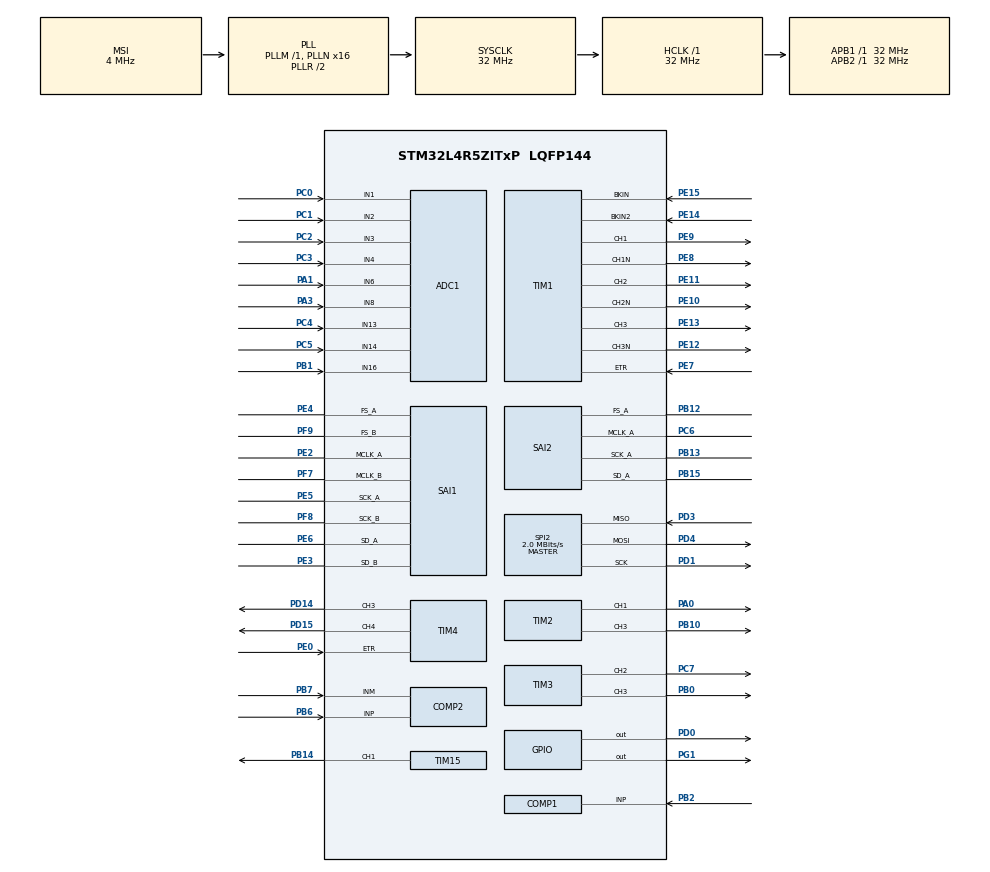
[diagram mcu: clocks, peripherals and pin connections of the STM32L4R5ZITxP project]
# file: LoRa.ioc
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ADC1.Channel-0\#ChannelRegularConversion=ADC_CHANNEL_1
ADC1.NbrOfConversionFlag=1
ADC1.OffsetNumber-0\#ChannelRegularConversion=ADC_OFFSET_NONE
ADC1.Rank-0\#ChannelRegularConversion=1
ADC1.SamplingTime-0\#ChannelRegularConversion=ADC_SAMPLETIME_2CYCLES_5
ADC1.master=1
Mcu.Family=STM32L4
Mcu.Name=STM32L4R5ZITxP
Mcu.Package=LQFP144
NVIC.PriorityGroup=NVIC_PRIORITYGROUP_4
PA0.Signal=S_TIM2_CH1
PA1.Signal=ADCx_IN6
PA10.Signal=USB_OTG_FS_ID
PA13\ (JTMS/SWDIO).Mode=Serial_Wire
PA13\ (JTMS/SWDIO).Signal=SYS_JTMS-SWDIO
PA14\ (JTCK/SWCLK).Mode=Serial_Wire
PA14\ (JTCK/SWCLK).Signal=SYS_JTCK-SWCLK
PA3.Signal=ADCx_IN8
PA4.Signal=SPI1_NSS
PA5.Signal=SPI1_SCK
PA6.Signal=SPI1_MISO
PA7.Signal=SPI1_MOSI
PA8.Signal=USB_OTG_FS_SOF
PA9.Signal=USB_OTG_FS_VBUS
PB0.Signal=S_TIM3_CH3
PB1.Signal=ADCx_IN16
PB10.Signal=S_TIM2_CH3
PB12.Mode=SAI_A_MasterWithClock
PB12.Signal=SAI2_FS_A
PB13.Mode=SAI_A_MasterWithClock
PB13.Signal=SAI2_SCK_A
PB14.Signal=S_TIM15_CH1
PB15.Mode=SAI_A_MasterWithClock
PB15.Signal=SAI2_SD_A
PB2.Mode=INP
PB2.Signal=COMP1_INP
PB3\ (JTDO/TRACESWO).Signal=SPI3_SCK
PB4\ (NJTRST).Signal=SPI3_MISO
PB5.Signal=SPI3_MOSI
PB6.Mode=INP
PB6.Signal=COMP2_INP
PB7.Mode=INM
PB7.Signal=COMP2_INM
PB8.GPIO_Pu=GPIO_PULLUP
PB8.Signal=I2C1_SCL
PB9.GPIO_Pu=GPIO_PULLUP
PB9.Signal=I2C1_SDA
PC0.Signal=ADCx_IN1
PC1.Signal=ADCx_IN2
PC10.Signal=SDMMC1_D2
PC11.Signal=SDMMC1_D3
PC12.Signal=SDMMC1_CK
PC13.Mode=SYS_WakeUp1
PC13.Signal=SYS_WKUP2
PC14-OSC32_IN\ (PC14).Mode=LSE-External-Oscillator
PC14-OSC32_IN\ (PC14).Signal=RCC_OSC32_IN
PC15-OSC32_OUT\ (PC15).Mode=LSE-External-Oscillator
PC15-OSC32_OUT\ (PC15).Signal=RCC_OSC32_OUT
PC2.Signal=ADCx_IN3
PC3.Signal=ADCx_IN4
PC4.Signal=ADCx_IN13
PC5.Signal=ADCx_IN14
PC6.Mode=SAI_A_MasterWithClock
PC6.Signal=SAI2_MCLK_A
PC7.Signal=S_TIM3_CH2
PC8.Signal=SDMMC1_D0
PC9.Signal=SDMMC1_D1
PD0.PinState=GPIO_PIN_SET
PD0.Signal=GPIO_Output
PD1.Mode=Full_Duplex_Master
PD1.Signal=SPI2_SCK
PD14.Signal=S_TIM4_CH3
PD15.Signal=S_TIM4_CH4
PD2.Signal=SDMMC1_CMD
PD3.Mode=Full_Duplex_Master
PD3.Signal=SPI2_MISO
PD4.Mode=Full_Duplex_Master
PD4.Signal=SPI2_MOSI
PD5.Signal=USART2_TX
PD6.Signal=USART2_RX
PD8.Signal=USART3_TX
PD9.Signal=USART3_RX
PE0.Signal=S_TIM4_ETR
PE10.Mode=PWM Generation2 CH2 CH2N
PE10.Signal=TIM1_CH2N
PE11.Signal=S_TIM1_CH2
PE12.Mode=PWM Generation3 CH3 CH3N
PE12.Signal=TIM1_CH3N
PE13.Signal=S_TIM1_CH3
PE14.Mode=Activate-Break-Input-2
PE14.Signal=TIM1_BKIN2
PE15.Mode=Activate-Break-Input
PE15.Signal=TIM1_BKIN
PE2.Mode=SAI_A_MasterWithClock
PE2.Signal=SAI1_MCLK_A
PE3.Mode=SAI_B_MasterWithClock
PE3.Signal=SAI1_SD_B
PE4.Mode=SAI_A_MasterWithClock
PE4.Signal=SAI1_FS_A
PE5.Mode=SAI_A_MasterWithClock
PE5.Signal=SAI1_SCK_A
PE6.Mode=SAI_A_MasterWithClock
PE6.Signal=SAI1_SD_A
PE7.Signal=S_TIM1_ETR
PE8.Mode=PWM Generation1 CH1 CH1N
PE8.Signal=TIM1_CH1N
PE9.Signal=S_TIM1_CH1
PF0.GPIO_Pu=GPIO_PULLUP
PF0.Signal=I2C2_SDA
PF1.GPIO_Pu=GPIO_PULLUP
PF1.Signal=I2C2_SCL
PF2.GPIO_Pu=GPIO_PULLUP
PF2.Signal=I2C2_SMBA
PF7.Mode=SAI_B_MasterWithClock
PF7.Signal=SAI1_MCLK_B
PF8.Mode=SAI_B_MasterWithClock
PF8.Signal=SAI1_SCK_B
PF9.Mode=SAI_B_MasterWithClock
PF9.Signal=SAI1_FS_B
PG1.Signal=GPIO_Output
PG7.Signal=LPUART1_TX
PG8.Signal=LPUART1_RX
PH0-OSC_IN\ (PH0).Mode=HSE-External-Oscillator
PH0-OSC_IN\ (PH0).Signal=RCC_OSC_IN
PH1-OSC_OUT\ (PH1).Mode=HSE-External-Oscillator
PH1-OSC_OUT\ (PH1).Signal=RCC_OSC_OUT
ProjectManager.HeapSize=0x200
ProjectManager.StackSize=0x400
ProjectManager.TargetToolchain=STM32CubeIDE
RCC.ADCFreq_Value=48000000
RCC.AHBFreq_Value=32000000
RCC.APB1Freq_Value=32000000
RCC.APB1TimFreq_Value=32000000
RCC.APB2Freq_Value=32000000
RCC.APB2TimFreq_Value=32000000
RCC.CortexFreq_Value=32000000
RCC.HCLKFreq_Value=32000000
RCC.HSE_VALUE=8000000
RCC.HSI48_VALUE=48000000
RCC.HSI_VALUE=16000000
RCC.MSI_VALUE=4000000
RCC.PLLN=16
RCC.PLLSAI1N=24
RCC.SYSCLKFreq_VALUE=32000000
RCC.SYSCLKSource=RCC_SYSCLKSOURCE_PLLCLK
RCC.USBFreq_Value=48000000
RCC.VCOOutputFreq_Value=64000000
SAI1.InitProtocol-SAI_A_MasterWithClock=Enable
SAI1.Instance-SAI_A_MasterWithClock=SAI$Index_Block_A
SAI1.Instance-SAI_B_MasterWithClock=SAI$Index_Block_B
SAI1.MClockEnable-SAI_A_MasterWithClock=SAI_MASTERCLOCK_ENABLE
SAI1.MClockEnable-SAI_B_MasterWithClock=SAI_MASTERCLOCK_ENABLE
SAI1.Synchro-SAI_A_MasterWithClock=SAI_ASYNCHRONOUS
SAI1.Synchro-SAI_B_MasterWithClock=SAI_ASYNCHRONOUS
SAI1.VirtualMode-SAI_A_MasterWithClock=VM_MASTER
SAI1.VirtualMode-SAI_B_MasterWithClock=VM_MASTER
SAI1.VirtualProtocol-SAI_A_BASIC=VM_BASIC_PROTOCOL
SAI2.Instance-SAI_A_MasterWithClock=SAI$Index_Block_A
SAI2.MClockEnable-SAI_A_MasterWithClock=SAI_MASTERCLOCK_ENABLE
SAI2.Synchro-SAI_A_MasterWithClock=SAI_ASYNCHRONOUS
SAI2.VirtualMode-SAI_A_MasterWithClock=VM_MASTER
SH.ADCx_IN1.0=ADC1_IN1,IN1-Single-Ended
SH.ADCx_IN13.0=ADC1_IN13,IN13-Single-Ended
SH.ADCx_IN14.0=ADC1_IN14,IN14-Single-Ended
SH.ADCx_IN16.0=ADC1_IN16,IN16-Single-Ended
SH.ADCx_IN2.0=ADC1_IN2,IN2-Single-Ended
SH.ADCx_IN3.0=ADC1_IN3,IN3-Single-Ended
SH.ADCx_IN4.0=ADC1_IN4,IN4-Single-Ended
SH.ADCx_IN6.0=ADC1_IN6,IN6-Single-Ended
SH.ADCx_IN8.0=ADC1_IN8,IN8-Single-Ended
SH.S_TIM15_CH1.0=TIM15_CH1,PWM Generation1 CH1
SH.S_TIM1_CH1.0=TIM1_CH1,PWM Generation1 CH1 CH1N
SH.S_TIM1_CH2.0=TIM1_CH2,PWM Generation2 CH2 CH2N
SH.S_TIM1_CH3.0=TIM1_CH3,PWM Generation3 CH3 CH3N
SH.S_TIM1_ETR.0=TIM1_ETR,ETR-as-clearing-source
SH.S_TIM2_CH1.0=TIM2_CH1,PWM Generation1 CH1
SH.S_TIM2_CH3.0=TIM2_CH3,PWM Generation3 CH3
SH.S_TIM3_CH2.0=TIM3_CH2,PWM Generation2 CH2
SH.S_TIM3_CH3.0=TIM3_CH3,PWM Generation3 CH3
SH.S_TIM4_CH3.0=TIM4_CH3,PWM Generation3 CH3
SH.S_TIM4_CH4.0=TIM4_CH4,PWM Generation4 CH4
SH.S_TIM4_ETR.0=TIM4_ETR,ETR-as-clearing-source
SPI2.BaudRatePrescaler=SPI_BAUDRATEPRESCALER_16
SPI2.CalculateBaudRate=2.0 MBits/s
SPI2.DataSize=SPI_DATASIZE_8BIT
SPI2.Direction=SPI_DIRECTION_2LINES
SPI2.Mode=SPI_MODE_MASTER
SPI2.VirtualType=VM_MASTER
TIM1.Channel-PWM\ Generation1\ CH1\ CH1N=TIM_CHANNEL_1
TIM1.Channel-PWM\ Generation2\ CH2\ CH2N=TIM_CHANNEL_2
TIM1.Channel-PWM\ Generation3\ CH3\ CH3N=TIM_CHANNEL_3
TIM15.Channel-PWM\ Generation1\ CH1=TIM_CHANNEL_1
TIM2.Channel-PWM\ Generation1\ CH1=TIM_CHANNEL_1
TIM2.Channel-PWM\ Generation3\ CH3=TIM_CHANNEL_3
TIM3.Channel-PWM\ Generation2\ CH2=TIM_CHANNEL_2
TIM3.Channel-PWM\ Generation3\ CH3=TIM_CHANNEL_3
TIM4.Channel-PWM\ Generation3\ CH3=TIM_CHANNEL_3
TIM4.Channel-PWM\ Generation4\ CH4=TIM_CHANNEL_4
VP_COMP1_VS_VREFINT.Mode=VREFINT
VP_SAI1_VP_$IpInstance_SAIA_SAI_BASIC.Mode=SAI_A_BASIC
board=NUCLEO-L4R5ZI-P

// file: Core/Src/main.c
/* USER CODE BEGIN Header */
/**
  ******************************************************************************
  * @file           : main.c
  * @brief          : Main program body
  ******************************************************************************
  * @attention
  *
  * Copyright (c) 2024 STMicroelectronics.
  * All rights reserved.
  *
  * This software is licensed under terms that can be found in the LICENSE file
  * in the root directory of this software component.
  * If no LICENSE file comes with this software, it is provided AS-IS.
  *
  ******************************************************************************
  */
/* USER CODE END Header */
#include "main.h"

/* USER CODE BEGIN Includes */
#include "lora_sx1276.h"
/* USER CODE END Includes */

/* USER CODE BEGIN PD */
//#define RADIO_INIT_REGISTERS_VALUE                \
//{                                                 \
//    { MODEM_FSK , REG_LNA                , 0x23 },\
//    { MODEM_FSK , REG_RXCONFIG           , 0x1E },\
//    { MODEM_FSK , REG_RSSICONFIG         , 0xD2 },\
//    { MODEM_FSK , REG_AFCFEI             , 0x01 },\
//    { MODEM_FSK , REG_PREAMBLEDETECT     , 0xAA },\
//    { MODEM_FSK , REG_OSC                , 0x07 },\
//    { MODEM_FSK , REG_SYNCCONFIG         , 0x12 },\
//    { MODEM_FSK , REG_SYNCVALUE1         , 0xC1 },\
//    { MODEM_FSK , REG_SYNCVALUE2         , 0x94 },\
//    { MODEM_FSK , REG_SYNCVALUE3         , 0xC1 },\
//    { MODEM_FSK , REG_PACKETCONFIG1      , 0xD8 },\
//    { MODEM_FSK , REG_FIFOTHRESH         , 0x8F },\
//    { MODEM_FSK , REG_IMAGECAL           , 0x02 },\
//    { MODEM_FSK , REG_DIOMAPPING1        , 0x00 },\
//    { MODEM_FSK , REG_DIOMAPPING2        , 0x30 },\
//    { MODEM_LORA, REG_LR_PAYLOADMAXLENGTH, 0x40 },\
//}
/* USER CODE END PD */

ADC_HandleTypeDef hadc1;

COMP_HandleTypeDef hcomp1;
COMP_HandleTypeDef hcomp2;

SAI_HandleTypeDef hsai_BlockB1;
SAI_HandleTypeDef hsai_BlockA1;
SAI_HandleTypeDef hsai_BlockA2;

SPI_HandleTypeDef hspi2;

TIM_HandleTypeDef htim1;
TIM_HandleTypeDef htim2;
TIM_HandleTypeDef htim3;
TIM_HandleTypeDef htim4;
TIM_HandleTypeDef htim15;

void SystemClock_Config(void);
void PeriphCommonClock_Config(void);
static void MX_GPIO_Init(void);
static void MX_ADC1_Init(void);
static void MX_COMP1_Init(void);
static void MX_COMP2_Init(void);
static void MX_SAI1_Init(void);
static void MX_SAI2_Init(void);
static void MX_TIM1_Init(void);
static void MX_TIM2_Init(void);
static void MX_TIM3_Init(void);
static void MX_TIM4_Init(void);
static void MX_TIM15_Init(void);
static void MX_SPI2_Init(void);

int main(void)
{

  /* MCU Configuration--------------------------------------------------------*/

  /* Reset of all peripherals, Initializes the Flash interface and the Systick. */
  HAL_Init();

  /* Configure the system clock */
  SystemClock_Config();

/* Configure the peripherals common clocks */
  PeriphCommonClock_Config();

  /* Initialize all configured peripherals */
  MX_GPIO_Init();
  MX_ADC1_Init();
  MX_COMP1_Init();
  MX_COMP2_Init();
  MX_SAI1_Init();
  MX_SAI2_Init();
  MX_TIM1_Init();
  MX_TIM2_Init();
  MX_TIM3_Init();
  MX_TIM4_Init();
  MX_TIM15_Init();
  MX_SPI2_Init();
  /* USER CODE BEGIN 2 */

  // msaon test code
//  HAL_GPIO_WritePin(GPIOD, GPIO_PIN_0, 1 );
//  HAL_Delay(5);
//  HAL_GPIO_WritePin(GPIOD, GPIO_PIN_0, 0 );
//  HAL_Delay(5);
//  HAL_GPIO_WritePin(GPIOD, GPIO_PIN_0, 1 );
//  HAL_Delay(5);

//  uint8_t temporary[3] = {0xde, 0xad, 0xbe};
//  HAL_SPI_Transmit(&hspi2, &temporary[0], 1, 1000);

  // send
//  HAL_SPI_Transmit(&hspi2, 0x00, 0, HAL_MAX_DELAY);
//  HAL
  lora_sx1276 lora;

    // SX1276 compatible module connected to SPI1, NSS pin connected to GPIO with label LORA_NSS
    uint8_t res = lora_init(&lora, &hspi2, GPIOD, GPIO_PIN_0, LORA_BASE_FREQUENCY_US+FREQ_OFFSET);
    if (res != LORA_OK) {
      // Initialization failed
    }

  /* USER CODE END 2 */

  /* Infinite loop */
  while (1)
  {

    /* USER CODE BEGIN 3 */
	  uint8_t buffer[32];
	  lora_mode_receive_continuous(&lora);
	  uint8_t res;
	  uint8_t len = lora_receive_packet_blocking(&lora, buffer, sizeof(buffer), 10000, &res);
	  if (res != LORA_OK) {
		  // Receive failed
	  }
	  buffer[len] = 0; // null terminate string to print it
  }
  /* USER CODE END 3 */
}

void SystemClock_Config(void)
{
  RCC_OscInitTypeDef RCC_OscInitStruct = {0};
  RCC_ClkInitTypeDef RCC_ClkInitStruct = {0};

  /** Configure the main internal regulator output voltage
  */
  if (HAL_PWREx_ControlVoltageScaling(PWR_REGULATOR_VOLTAGE_SCALE1) != HAL_OK)
  {
    Error_Handler();
  }

  /** Initializes the RCC Oscillators according to the specified parameters
  * in the RCC_OscInitTypeDef structure.
  */
  RCC_OscInitStruct.OscillatorType = RCC_OSCILLATORTYPE_MSI;
  RCC_OscInitStruct.MSIState = RCC_MSI_ON;
  RCC_OscInitStruct.MSICalibrationValue = 0;
  RCC_OscInitStruct.MSIClockRange = RCC_MSIRANGE_6;
  RCC_OscInitStruct.PLL.PLLState = RCC_PLL_ON;
  RCC_OscInitStruct.PLL.PLLSource = RCC_PLLSOURCE_MSI;
  RCC_OscInitStruct.PLL.PLLM = 1;
  RCC_OscInitStruct.PLL.PLLN = 16;
  RCC_OscInitStruct.PLL.PLLP = RCC_PLLP_DIV2;
  RCC_OscInitStruct.PLL.PLLQ = RCC_PLLQ_DIV2;
  RCC_OscInitStruct.PLL.PLLR = RCC_PLLR_DIV2;
  if (HAL_RCC_OscConfig(&RCC_OscInitStruct) != HAL_OK)
  {
    Error_Handler();
  }

  /** Initializes the CPU, AHB and APB buses clocks
  */
  RCC_ClkInitStruct.ClockType = RCC_CLOCKTYPE_HCLK|RCC_CLOCKTYPE_SYSCLK
                              |RCC_CLOCKTYPE_PCLK1|RCC_CLOCKTYPE_PCLK2;
  RCC_ClkInitStruct.SYSCLKSource = RCC_SYSCLKSOURCE_PLLCLK;
  RCC_ClkInitStruct.AHBCLKDivider = RCC_SYSCLK_DIV1;
  RCC_ClkInitStruct.APB1CLKDivider = RCC_HCLK_DIV1;
  RCC_ClkInitStruct.APB2CLKDivider = RCC_HCLK_DIV1;

  if (HAL_RCC_ClockConfig(&RCC_ClkInitStruct, FLASH_LATENCY_1) != HAL_OK)
  {
    Error_Handler();
  }
}

void PeriphCommonClock_Config(void)
{
  RCC_PeriphCLKInitTypeDef PeriphClkInit = {0};

  /** Initializes the peripherals clock
  */
  PeriphClkInit.PeriphClockSelection = RCC_PERIPHCLK_SAI1|RCC_PERIPHCLK_SAI2
                              |RCC_PERIPHCLK_ADC;
  PeriphClkInit.Sai1ClockSelection = RCC_SAI1CLKSOURCE_PLLSAI1;
  PeriphClkInit.Sai2ClockSelection = RCC_SAI2CLKSOURCE_PLLSAI1;
  PeriphClkInit.AdcClockSelection = RCC_ADCCLKSOURCE_PLLSAI1;
  PeriphClkInit.PLLSAI1.PLLSAI1Source = RCC_PLLSOURCE_MSI;
  PeriphClkInit.PLLSAI1.PLLSAI1M = 1;
  PeriphClkInit.PLLSAI1.PLLSAI1N = 24;
  PeriphClkInit.PLLSAI1.PLLSAI1P = RCC_PLLP_DIV2;
  PeriphClkInit.PLLSAI1.PLLSAI1Q = RCC_PLLQ_DIV2;
  PeriphClkInit.PLLSAI1.PLLSAI1R = RCC_PLLR_DIV2;
  PeriphClkInit.PLLSAI1.PLLSAI1ClockOut = RCC_PLLSAI1_SAI1CLK|RCC_PLLSAI1_ADC1CLK;
  if (HAL_RCCEx_PeriphCLKConfig(&PeriphClkInit) != HAL_OK)
  {
    Error_Handler();
  }
}

static void MX_ADC1_Init(void)
{

  ADC_ChannelConfTypeDef sConfig = {0};

  /** Common config
  */
  hadc1.Instance = ADC1;
  hadc1.Init.ClockPrescaler = ADC_CLOCK_ASYNC_DIV1;
  hadc1.Init.Resolution = ADC_RESOLUTION_12B;
  hadc1.Init.DataAlign = ADC_DATAALIGN_RIGHT;
  hadc1.Init.ScanConvMode = ADC_SCAN_DISABLE;
  hadc1.Init.EOCSelection = ADC_EOC_SINGLE_CONV;
  hadc1.Init.LowPowerAutoWait = DISABLE;
  hadc1.Init.ContinuousConvMode = DISABLE;
  hadc1.Init.NbrOfConversion = 1;
  hadc1.Init.DiscontinuousConvMode = DISABLE;
  hadc1.Init.ExternalTrigConv = ADC_SOFTWARE_START;
  hadc1.Init.ExternalTrigConvEdge = ADC_EXTERNALTRIGCONVEDGE_NONE;
  hadc1.Init.DMAContinuousRequests = DISABLE;
  hadc1.Init.Overrun = ADC_OVR_DATA_PRESERVED;
  hadc1.Init.OversamplingMode = DISABLE;
  if (HAL_ADC_Init(&hadc1) != HAL_OK)
  {
    Error_Handler();
  }

  /** Configure Regular Channel
  */
  sConfig.Channel = ADC_CHANNEL_1;
  sConfig.Rank = ADC_REGULAR_RANK_1;
  sConfig.SamplingTime = ADC_SAMPLETIME_2CYCLES_5;
  sConfig.SingleDiff = ADC_SINGLE_ENDED;
  sConfig.OffsetNumber = ADC_OFFSET_NONE;
  sConfig.Offset = 0;
  if (HAL_ADC_ConfigChannel(&hadc1, &sConfig) != HAL_OK)
  {
    Error_Handler();
  }

}

static void MX_COMP1_Init(void)
{

  hcomp1.Instance = COMP1;
  hcomp1.Init.InvertingInput = COMP_INPUT_MINUS_VREFINT;
  hcomp1.Init.NonInvertingInput = COMP_INPUT_PLUS_IO2;
  hcomp1.Init.OutputPol = COMP_OUTPUTPOL_NONINVERTED;
  hcomp1.Init.Hysteresis = COMP_HYSTERESIS_NONE;
  hcomp1.Init.BlankingSrce = COMP_BLANKINGSRC_NONE;
  hcomp1.Init.Mode = COMP_POWERMODE_HIGHSPEED;
  hcomp1.Init.WindowMode = COMP_WINDOWMODE_DISABLE;
  hcomp1.Init.TriggerMode = COMP_TRIGGERMODE_NONE;
  if (HAL_COMP_Init(&hcomp1) != HAL_OK)
  {
    Error_Handler();
  }

}

static void MX_COMP2_Init(void)
{

  hcomp2.Instance = COMP2;
  hcomp2.Init.InvertingInput = COMP_INPUT_MINUS_IO2;
  hcomp2.Init.NonInvertingInput = COMP_INPUT_PLUS_IO2;
  hcomp2.Init.OutputPol = COMP_OUTPUTPOL_NONINVERTED;
  hcomp2.Init.Hysteresis = COMP_HYSTERESIS_NONE;
  hcomp2.Init.BlankingSrce = COMP_BLANKINGSRC_NONE;
  hcomp2.Init.Mode = COMP_POWERMODE_HIGHSPEED;
  hcomp2.Init.WindowMode = COMP_WINDOWMODE_DISABLE;
  hcomp2.Init.TriggerMode = COMP_TRIGGERMODE_NONE;
  if (HAL_COMP_Init(&hcomp2) != HAL_OK)
  {
    Error_Handler();
  }

}

static void MX_SAI1_Init(void)
{

  hsai_BlockB1.Instance = SAI1_Block_B;
  hsai_BlockB1.Init.Protocol = SAI_FREE_PROTOCOL;
  hsai_BlockB1.Init.AudioMode = SAI_MODEMASTER_TX;
  hsai_BlockB1.Init.DataSize = SAI_DATASIZE_8;
  hsai_BlockB1.Init.FirstBit = SAI_FIRSTBIT_MSB;
  hsai_BlockB1.Init.ClockStrobing = SAI_CLOCKSTROBING_FALLINGEDGE;
  hsai_BlockB1.Init.Synchro = SAI_ASYNCHRONOUS;
  hsai_BlockB1.Init.OutputDrive = SAI_OUTPUTDRIVE_DISABLE;
  hsai_BlockB1.Init.NoDivider = SAI_MASTERDIVIDER_ENABLE;
  hsai_BlockB1.Init.MckOverSampling = SAI_MCK_OVERSAMPLING_DISABLE;
  hsai_BlockB1.Init.FIFOThreshold = SAI_FIFOTHRESHOLD_EMPTY;
  hsai_BlockB1.Init.AudioFrequency = SAI_AUDIO_FREQUENCY_192K;
  hsai_BlockB1.Init.SynchroExt = SAI_SYNCEXT_DISABLE;
  hsai_BlockB1.Init.MonoStereoMode = SAI_STEREOMODE;
  hsai_BlockB1.Init.CompandingMode = SAI_NOCOMPANDING;
  hsai_BlockB1.Init.TriState = SAI_OUTPUT_NOTRELEASED;
  hsai_BlockB1.Init.PdmInit.Activation = DISABLE;
  hsai_BlockB1.Init.PdmInit.MicPairsNbr = 0;
  hsai_BlockB1.Init.PdmInit.ClockEnable = SAI_PDM_CLOCK1_ENABLE;
  hsai_BlockB1.FrameInit.FrameLength = 8;
  hsai_BlockB1.FrameInit.ActiveFrameLength = 1;
  hsai_BlockB1.FrameInit.FSDefinition = SAI_FS_STARTFRAME;
  hsai_BlockB1.FrameInit.FSPolarity = SAI_FS_ACTIVE_LOW;
  hsai_BlockB1.FrameInit.FSOffset = SAI_FS_FIRSTBIT;
  hsai_BlockB1.SlotInit.FirstBitOffset = 0;
  hsai_BlockB1.SlotInit.SlotSize = SAI_SLOTSIZE_DATASIZE;
  hsai_BlockB1.SlotInit.SlotNumber = 1;
  hsai_BlockB1.SlotInit.SlotActive = 0x00000000;
  if (HAL_SAI_Init(&hsai_BlockB1) != HAL_OK)
  {
    Error_Handler();
  }
  hsai_BlockA1.Instance = SAI1_Block_A;
  hsai_BlockA1.Init.AudioMode = SAI_MODEMASTER_TX;
  hsai_BlockA1.Init.Synchro = SAI_ASYNCHRONOUS;
  hsai_BlockA1.Init.OutputDrive = SAI_OUTPUTDRIVE_DISABLE;
  hsai_BlockA1.Init.NoDivider = SAI_MASTERDIVIDER_ENABLE;
  hsai_BlockA1.Init.FIFOThreshold = SAI_FIFOTHRESHOLD_EMPTY;
  hsai_BlockA1.Init.AudioFrequency = SAI_AUDIO_FREQUENCY_192K;
  hsai_BlockA1.Init.SynchroExt = SAI_SYNCEXT_DISABLE;
  hsai_BlockA1.Init.MonoStereoMode = SAI_STEREOMODE;
  hsai_BlockA1.Init.CompandingMode = SAI_NOCOMPANDING;
  hsai_BlockA1.Init.TriState = SAI_OUTPUT_NOTRELEASED;
  if (HAL_SAI_InitProtocol(&hsai_BlockA1, SAI_I2S_STANDARD, SAI_PROTOCOL_DATASIZE_16BIT, 2) != HAL_OK)
  {
    Error_Handler();
  }

}

static void MX_SAI2_Init(void)
{

  hsai_BlockA2.Instance = SAI2_Block_A;
  hsai_BlockA2.Init.Protocol = SAI_FREE_PROTOCOL;
  hsai_BlockA2.Init.AudioMode = SAI_MODEMASTER_TX;
  hsai_BlockA2.Init.DataSize = SAI_DATASIZE_8;
  hsai_BlockA2.Init.FirstBit = SAI_FIRSTBIT_MSB;
  hsai_BlockA2.Init.ClockStrobing = SAI_CLOCKSTROBING_FALLINGEDGE;
  hsai_BlockA2.Init.Synchro = SAI_ASYNCHRONOUS;
  hsai_BlockA2.Init.OutputDrive = SAI_OUTPUTDRIVE_DISABLE;
  hsai_BlockA2.Init.NoDivider = SAI_MASTERDIVIDER_ENABLE;
  hsai_BlockA2.Init.MckOverSampling = SAI_MCK_OVERSAMPLING_DISABLE;
  hsai_BlockA2.Init.FIFOThreshold = SAI_FIFOTHRESHOLD_EMPTY;
  hsai_BlockA2.Init.AudioFrequency = SAI_AUDIO_FREQUENCY_192K;
  hsai_BlockA2.Init.SynchroExt = SAI_SYNCEXT_DISABLE;
  hsai_BlockA2.Init.MonoStereoMode = SAI_STEREOMODE;
  hsai_BlockA2.Init.CompandingMode = SAI_NOCOMPANDING;
  hsai_BlockA2.Init.TriState = SAI_OUTPUT_NOTRELEASED;
  hsai_BlockA2.Init.PdmInit.Activation = DISABLE;
  hsai_BlockA2.Init.PdmInit.MicPairsNbr = 0;
  hsai_BlockA2.Init.PdmInit.ClockEnable = SAI_PDM_CLOCK1_ENABLE;
  hsai_BlockA2.FrameInit.FrameLength = 8;
  hsai_BlockA2.FrameInit.ActiveFrameLength = 1;
  hsai_BlockA2.FrameInit.FSDefinition = SAI_FS_STARTFRAME;
  hsai_BlockA2.FrameInit.FSPolarity = SAI_FS_ACTIVE_LOW;
  hsai_BlockA2.FrameInit.FSOffset = SAI_FS_FIRSTBIT;
  hsai_BlockA2.SlotInit.FirstBitOffset = 0;
  hsai_BlockA2.SlotInit.SlotSize = SAI_SLOTSIZE_DATASIZE;
  hsai_BlockA2.SlotInit.SlotNumber = 1;
  hsai_BlockA2.SlotInit.SlotActive = 0x00000000;
  if (HAL_SAI_Init(&hsai_BlockA2) != HAL_OK)
  {
    Error_Handler();
  }

}

static void MX_SPI2_Init(void)
{

  /* SPI2 parameter configuration*/
  hspi2.Instance = SPI2;
  hspi2.Init.Mode = SPI_MODE_MASTER;
  hspi2.Init.Direction = SPI_DIRECTION_2LINES;
  hspi2.Init.DataSize = SPI_DATASIZE_8BIT;
  hspi2.Init.CLKPolarity = SPI_POLARITY_LOW;
  hspi2.Init.CLKPhase = SPI_PHASE_1EDGE;
  hspi2.Init.NSS = SPI_NSS_SOFT;
  hspi2.Init.BaudRatePrescaler = SPI_BAUDRATEPRESCALER_16;
  hspi2.Init.FirstBit = SPI_FIRSTBIT_MSB;
  hspi2.Init.TIMode = SPI_TIMODE_DISABLE;
  hspi2.Init.CRCCalculation = SPI_CRCCALCULATION_DISABLE;
  hspi2.Init.CRCPolynomial = 7;
  hspi2.Init.CRCLength = SPI_CRC_LENGTH_DATASIZE;
  hspi2.Init.NSSPMode = SPI_NSS_PULSE_ENABLE;
  if (HAL_SPI_Init(&hspi2) != HAL_OK)
  {
    Error_Handler();
  }

}

static void MX_TIM1_Init(void)
{

  TIM_MasterConfigTypeDef sMasterConfig = {0};
  TIMEx_BreakInputConfigTypeDef sBreakInputConfig = {0};
  TIM_OC_InitTypeDef sConfigOC = {0};
  TIM_BreakDeadTimeConfigTypeDef sBreakDeadTimeConfig = {0};

  htim1.Instance = TIM1;
  htim1.Init.Prescaler = 0;
  htim1.Init.CounterMode = TIM_COUNTERMODE_UP;
  htim1.Init.Period = 65535;
  htim1.Init.ClockDivision = TIM_CLOCKDIVISION_DIV1;
  htim1.Init.RepetitionCounter = 0;
  htim1.Init.AutoReloadPreload = TIM_AUTORELOAD_PRELOAD_DISABLE;
  if (HAL_TIM_PWM_Init(&htim1) != HAL_OK)
  {
    Error_Handler();
  }
  sMasterConfig.MasterOutputTrigger = TIM_TRGO_RESET;
  sMasterConfig.MasterOutputTrigger2 = TIM_TRGO2_RESET;
  sMasterConfig.MasterSlaveMode = TIM_MASTERSLAVEMODE_DISABLE;
  if (HAL_TIMEx_MasterConfigSynchronization(&htim1, &sMasterConfig) != HAL_OK)
  {
    Error_Handler();
  }
  sBreakInputConfig.Source = TIM_BREAKINPUTSOURCE_BKIN;
  sBreakInputConfig.Enable = TIM_BREAKINPUTSOURCE_ENABLE;
  sBreakInputConfig.Polarity = TIM_BREAKINPUTSOURCE_POLARITY_HIGH;
  if (HAL_TIMEx_ConfigBreakInput(&htim1, TIM_BREAKINPUT_BRK, &sBreakInputConfig) != HAL_OK)
  {
    Error_Handler();
  }
  if (HAL_TIMEx_ConfigBreakInput(&htim1, TIM_BREAKINPUT_BRK2, &sBreakInputConfig) != HAL_OK)
  {
    Error_Handler();
  }
  sConfigOC.OCMode = TIM_OCMODE_PWM1;
  sConfigOC.Pulse = 0;
  sConfigOC.OCPolarity = TIM_OCPOLARITY_HIGH;
  sConfigOC.OCNPolarity = TIM_OCNPOLARITY_HIGH;
  sConfigOC.OCFastMode = TIM_OCFAST_DISABLE;
  sConfigOC.OCIdleState = TIM_OCIDLESTATE_RESET;
  sConfigOC.OCNIdleState = TIM_OCNIDLESTATE_RESET;
  if (HAL_TIM_PWM_ConfigChannel(&htim1, &sConfigOC, TIM_CHANNEL_1) != HAL_OK)
  {
    Error_Handler();
  }
  if (HAL_TIM_PWM_ConfigChannel(&htim1, &sConfigOC, TIM_CHANNEL_2) != HAL_OK)
  {
    Error_Handler();
  }
  if (HAL_TIM_PWM_ConfigChannel(&htim1, &sConfigOC, TIM_CHANNEL_3) != HAL_OK)
  {
    Error_Handler();
  }
  sBreakDeadTimeConfig.OffStateRunMode = TIM_OSSR_ENABLE;
  sBreakDeadTimeConfig.OffStateIDLEMode = TIM_OSSI_ENABLE;
  sBreakDeadTimeConfig.LockLevel = TIM_LOCKLEVEL_OFF;
  sBreakDeadTimeConfig.DeadTime = 0;
  sBreakDeadTimeConfig.BreakState = TIM_BREAK_ENABLE;
  sBreakDeadTimeConfig.BreakPolarity = TIM_BREAKPOLARITY_HIGH;
  sBreakDeadTimeConfig.BreakFilter = 0;
  sBreakDeadTimeConfig.Break2State = TIM_BREAK2_ENABLE;
  sBreakDeadTimeConfig.Break2Polarity = TIM_BREAK2POLARITY_HIGH;
  sBreakDeadTimeConfig.Break2Filter = 0;
  sBreakDeadTimeConfig.AutomaticOutput = TIM_AUTOMATICOUTPUT_DISABLE;
  if (HAL_TIMEx_ConfigBreakDeadTime(&htim1, &sBreakDeadTimeConfig) != HAL_OK)
  {
    Error_Handler();
  }
  HAL_TIM_MspPostInit(&htim1);

}

static void MX_TIM2_Init(void)
{

  TIM_MasterConfigTypeDef sMasterConfig = {0};
  TIM_OC_InitTypeDef sConfigOC = {0};

  htim2.Instance = TIM2;
  htim2.Init.Prescaler = 0;
  htim2.Init.CounterMode = TIM_COUNTERMODE_UP;
  htim2.Init.Period = 4294967295;
  htim2.Init.ClockDivision = TIM_CLOCKDIVISION_DIV1;
  htim2.Init.AutoReloadPreload = TIM_AUTORELOAD_PRELOAD_DISABLE;
  if (HAL_TIM_PWM_Init(&htim2) != HAL_OK)
  {
    Error_Handler();
  }
  sMasterConfig.MasterOutputTrigger = TIM_TRGO_RESET;
  sMasterConfig.MasterSlaveMode = TIM_MASTERSLAVEMODE_DISABLE;
  if (HAL_TIMEx_MasterConfigSynchronization(&htim2, &sMasterConfig) != HAL_OK)
  {
    Error_Handler();
  }
  sConfigOC.OCMode = TIM_OCMODE_PWM1;
  sConfigOC.Pulse = 0;
  sConfigOC.OCPolarity = TIM_OCPOLARITY_HIGH;
  sConfigOC.OCFastMode = TIM_OCFAST_DISABLE;
  if (HAL_TIM_PWM_ConfigChannel(&htim2, &sConfigOC, TIM_CHANNEL_1) != HAL_OK)
  {
    Error_Handler();
  }
  if (HAL_TIM_PWM_ConfigChannel(&htim2, &sConfigOC, TIM_CHANNEL_3) != HAL_OK)
  {
    Error_Handler();
  }
  HAL_TIM_MspPostInit(&htim2);

}

static void MX_TIM3_Init(void)
{

  TIM_MasterConfigTypeDef sMasterConfig = {0};
  TIM_OC_InitTypeDef sConfigOC = {0};

  htim3.Instance = TIM3;
  htim3.Init.Prescaler = 0;
  htim3.Init.CounterMode = TIM_COUNTERMODE_UP;
  htim3.Init.Period = 65535;
  htim3.Init.ClockDivision = TIM_CLOCKDIVISION_DIV1;
  htim3.Init.AutoReloadPreload = TIM_AUTORELOAD_PRELOAD_DISABLE;
  if (HAL_TIM_PWM_Init(&htim3) != HAL_OK)
  {
    Error_Handler();
  }
  sMasterConfig.MasterOutputTrigger = TIM_TRGO_RESET;
  sMasterConfig.MasterSlaveMode = TIM_MASTERSLAVEMODE_DISABLE;
  if (HAL_TIMEx_MasterConfigSynchronization(&htim3, &sMasterConfig) != HAL_OK)
  {
    Error_Handler();
  }
  sConfigOC.OCMode = TIM_OCMODE_PWM1;
  sConfigOC.Pulse = 0;
  sConfigOC.OCPolarity = TIM_OCPOLARITY_HIGH;
  sConfigOC.OCFastMode = TIM_OCFAST_DISABLE;
  if (HAL_TIM_PWM_ConfigChannel(&htim3, &sConfigOC, TIM_CHANNEL_2) != HAL_OK)
  {
    Error_Handler();
  }
  if (HAL_TIM_PWM_ConfigChannel(&htim3, &sConfigOC, TIM_CHANNEL_3) != HAL_OK)
  {
    Error_Handler();
  }
  HAL_TIM_MspPostInit(&htim3);

}

static void MX_TIM4_Init(void)
{

  TIM_MasterConfigTypeDef sMasterConfig = {0};
  TIM_OC_InitTypeDef sConfigOC = {0};

  htim4.Instance = TIM4;
  htim4.Init.Prescaler = 0;
  htim4.Init.CounterMode = TIM_COUNTERMODE_UP;
  htim4.Init.Period = 65535;
  htim4.Init.ClockDivision = TIM_CLOCKDIVISION_DIV1;
  htim4.Init.AutoReloadPreload = TIM_AUTORELOAD_PRELOAD_DISABLE;
  if (HAL_TIM_PWM_Init(&htim4) != HAL_OK)
  {
    Error_Handler();
  }
  sMasterConfig.MasterOutputTrigger = TIM_TRGO_RESET;
  sMasterConfig.MasterSlaveMode = TIM_MASTERSLAVEMODE_DISABLE;
  if (HAL_TIMEx_MasterConfigSynchronization(&htim4, &sMasterConfig) != HAL_OK)
  {
    Error_Handler();
  }
  sConfigOC.OCMode = TIM_OCMODE_PWM1;
  sConfigOC.Pulse = 0;
  sConfigOC.OCPolarity = TIM_OCPOLARITY_HIGH;
  sConfigOC.OCFastMode = TIM_OCFAST_DISABLE;
  if (HAL_TIM_PWM_ConfigChannel(&htim4, &sConfigOC, TIM_CHANNEL_3) != HAL_OK)
  {
    Error_Handler();
  }
  if (HAL_TIM_PWM_ConfigChannel(&htim4, &sConfigOC, TIM_CHANNEL_4) != HAL_OK)
  {
    Error_Handler();
  }
  HAL_TIM_MspPostInit(&htim4);

}

static void MX_TIM15_Init(void)
{

  TIM_MasterConfigTypeDef sMasterConfig = {0};
  TIM_OC_InitTypeDef sConfigOC = {0};
  TIM_BreakDeadTimeConfigTypeDef sBreakDeadTimeConfig = {0};

  htim15.Instance = TIM15;
  htim15.Init.Prescaler = 0;
  htim15.Init.CounterMode = TIM_COUNTERMODE_UP;
  htim15.Init.Period = 65535;
  htim15.Init.ClockDivision = TIM_CLOCKDIVISION_DIV1;
  htim15.Init.RepetitionCounter = 0;
  htim15.Init.AutoReloadPreload = TIM_AUTORELOAD_PRELOAD_DISABLE;
  if (HAL_TIM_PWM_Init(&htim15) != HAL_OK)
  {
    Error_Handler();
  }
  sMasterConfig.MasterOutputTrigger = TIM_TRGO_RESET;
  sMasterConfig.MasterSlaveMode = TIM_MASTERSLAVEMODE_DISABLE;
  if (HAL_TIMEx_MasterConfigSynchronization(&htim15, &sMasterConfig) != HAL_OK)
  {
    Error_Handler();
  }
  sConfigOC.OCMode = TIM_OCMODE_PWM1;
  sConfigOC.Pulse = 0;
  sConfigOC.OCPolarity = TIM_OCPOLARITY_HIGH;
  sConfigOC.OCNPolarity = TIM_OCNPOLARITY_HIGH;
  sConfigOC.OCFastMode = TIM_OCFAST_DISABLE;
  sConfigOC.OCIdleState = TIM_OCIDLESTATE_RESET;
  sConfigOC.OCNIdleState = TIM_OCNIDLESTATE_RESET;
  if (HAL_TIM_PWM_ConfigChannel(&htim15, &sConfigOC, TIM_CHANNEL_1) != HAL_OK)
  {
    Error_Handler();
  }
  sBreakDeadTimeConfig.OffStateRunMode = TIM_OSSR_DISABLE;
  sBreakDeadTimeConfig.OffStateIDLEMode = TIM_OSSI_DISABLE;
  sBreakDeadTimeConfig.LockLevel = TIM_LOCKLEVEL_OFF;
  sBreakDeadTimeConfig.DeadTime = 0;
  sBreakDeadTimeConfig.BreakState = TIM_BREAK_DISABLE;
  sBreakDeadTimeConfig.BreakPolarity = TIM_BREAKPOLARITY_HIGH;
  sBreakDeadTimeConfig.AutomaticOutput = TIM_AUTOMATICOUTPUT_DISABLE;
  if (HAL_TIMEx_ConfigBreakDeadTime(&htim15, &sBreakDeadTimeConfig) != HAL_OK)
  {
    Error_Handler();
  }
  HAL_TIM_MspPostInit(&htim15);

}

static void MX_GPIO_Init(void)
{
  GPIO_InitTypeDef GPIO_InitStruct = {0};

  /* GPIO Ports Clock Enable */
  __HAL_RCC_GPIOE_CLK_ENABLE();
  __HAL_RCC_GPIOC_CLK_ENABLE();
  __HAL_RCC_GPIOF_CLK_ENABLE();
  __HAL_RCC_GPIOH_CLK_ENABLE();
  __HAL_RCC_GPIOA_CLK_ENABLE();
  __HAL_RCC_GPIOB_CLK_ENABLE();
  __HAL_RCC_GPIOG_CLK_ENABLE();
  __HAL_RCC_GPIOD_CLK_ENABLE();
  HAL_PWREx_EnableVddIO2();

  /*Configure GPIO pin Output Level */
  HAL_GPIO_WritePin(GPIOG, GPIO_PIN_1, GPIO_PIN_RESET);

  /*Configure GPIO pin Output Level */
  HAL_GPIO_WritePin(GPIOD, GPIO_PIN_0, GPIO_PIN_RESET);

  /*Configure GPIO pins : PF0 PF1 PF2 */
  GPIO_InitStruct.Pin = GPIO_PIN_0|GPIO_PIN_1|GPIO_PIN_2;
  GPIO_InitStruct.Mode = GPIO_MODE_AF_OD;
  GPIO_InitStruct.Pull = GPIO_PULLUP;
  GPIO_InitStruct.Speed = GPIO_SPEED_FREQ_VERY_HIGH;
  GPIO_InitStruct.Alternate = GPIO_AF4_I2C2;
  HAL_GPIO_Init(GPIOF, &GPIO_InitStruct);

  /*Configure GPIO pins : PA4 PA5 PA6 PA7 */
  GPIO_InitStruct.Pin = GPIO_PIN_4|GPIO_PIN_5|GPIO_PIN_6|GPIO_PIN_7;
  GPIO_InitStruct.Mode = GPIO_MODE_AF_PP;
  GPIO_InitStruct.Pull = GPIO_NOPULL;
  GPIO_InitStruct.Speed = GPIO_SPEED_FREQ_VERY_HIGH;
  GPIO_InitStruct.Alternate = GPIO_AF5_SPI1;
  HAL_GPIO_Init(GPIOA, &GPIO_InitStruct);

  /*Configure GPIO pin : PG1 */
  GPIO_InitStruct.Pin = GPIO_PIN_1;
  GPIO_InitStruct.Mode = GPIO_MODE_OUTPUT_PP;
  GPIO_InitStruct.Pull = GPIO_NOPULL;
  GPIO_InitStruct.Speed = GPIO_SPEED_FREQ_LOW;
  HAL_GPIO_Init(GPIOG, &GPIO_InitStruct);

  /*Configure GPIO pins : PD8 PD9 */
  GPIO_InitStruct.Pin = GPIO_PIN_8|GPIO_PIN_9;
  GPIO_InitStruct.Mode = GPIO_MODE_AF_PP;
  GPIO_InitStruct.Pull = GPIO_NOPULL;
  GPIO_InitStruct.Speed = GPIO_SPEED_FREQ_VERY_HIGH;
  GPIO_InitStruct.Alternate = GPIO_AF7_USART3;
  HAL_GPIO_Init(GPIOD, &GPIO_InitStruct);

  /*Configure GPIO pins : PG7 PG8 */
  GPIO_InitStruct.Pin = GPIO_PIN_7|GPIO_PIN_8;
  GPIO_InitStruct.Mode = GPIO_MODE_AF_PP;
  GPIO_InitStruct.Pull = GPIO_NOPULL;
  GPIO_InitStruct.Speed = GPIO_SPEED_FREQ_VERY_HIGH;
  GPIO_InitStruct.Alternate = GPIO_AF8_LPUART1;
  HAL_GPIO_Init(GPIOG, &GPIO_InitStruct);

  /*Configure GPIO pins : PC8 PC9 PC10 PC11
                           PC12 */
  GPIO_InitStruct.Pin = GPIO_PIN_8|GPIO_PIN_9|GPIO_PIN_10|GPIO_PIN_11
                          |GPIO_PIN_12;
  GPIO_InitStruct.Mode = GPIO_MODE_AF_PP;
  GPIO_InitStruct.Pull = GPIO_NOPULL;
  GPIO_InitStruct.Speed = GPIO_SPEED_FREQ_VERY_HIGH;
  GPIO_InitStruct.Alternate = GPIO_AF12_SDMMC1;
  HAL_GPIO_Init(GPIOC, &GPIO_InitStruct);

  /*Configure GPIO pins : PA8 PA10 */
  GPIO_InitStruct.Pin = GPIO_PIN_8|GPIO_PIN_10;
  GPIO_InitStruct.Mode = GPIO_MODE_AF_PP;
  GPIO_InitStruct.Pull = GPIO_NOPULL;
  GPIO_InitStruct.Speed = GPIO_SPEED_FREQ_VERY_HIGH;
  GPIO_InitStruct.Alternate = GPIO_AF10_OTG_FS;
  HAL_GPIO_Init(GPIOA, &GPIO_InitStruct);

  /*Configure GPIO pin : PA9 */
  GPIO_InitStruct.Pin = GPIO_PIN_9;
  GPIO_InitStruct.Mode = GPIO_MODE_INPUT;
  GPIO_InitStruct.Pull = GPIO_NOPULL;
  HAL_GPIO_Init(GPIOA, &GPIO_InitStruct);

  /*Configure GPIO pin : PD0 */
  GPIO_InitStruct.Pin = GPIO_PIN_0;
  GPIO_InitStruct.Mode = GPIO_MODE_OUTPUT_PP;
  GPIO_InitStruct.Pull = GPIO_NOPULL;
  GPIO_InitStruct.Speed = GPIO_SPEED_FREQ_LOW;
  HAL_GPIO_Init(GPIOD, &GPIO_InitStruct);

  /*Configure GPIO pin : PD2 */
  GPIO_InitStruct.Pin = GPIO_PIN_2;
  GPIO_InitStruct.Mode = GPIO_MODE_AF_PP;
  GPIO_InitStruct.Pull = GPIO_NOPULL;
  GPIO_InitStruct.Speed = GPIO_SPEED_FREQ_VERY_HIGH;
  GPIO_InitStruct.Alternate = GPIO_AF12_SDMMC1;
  HAL_GPIO_Init(GPIOD, &GPIO_InitStruct);

  /*Configure GPIO pins : PD5 PD6 */
  GPIO_InitStruct.Pin = GPIO_PIN_5|GPIO_PIN_6;
  GPIO_InitStruct.Mode = GPIO_MODE_AF_PP;
  GPIO_InitStruct.Pull = GPIO_NOPULL;
  GPIO_InitStruct.Speed = GPIO_SPEED_FREQ_VERY_HIGH;
  GPIO_InitStruct.Alternate = GPIO_AF7_USART2;
  HAL_GPIO_Init(GPIOD, &GPIO_InitStruct);

  /*Configure GPIO pins : PB3 PB4 PB5 */
  GPIO_InitStruct.Pin = GPIO_PIN_3|GPIO_PIN_4|GPIO_PIN_5;
  GPIO_InitStruct.Mode = GPIO_MODE_AF_PP;
  GPIO_InitStruct.Pull = GPIO_NOPULL;
  GPIO_InitStruct.Speed = GPIO_SPEED_FREQ_VERY_HIGH;
  GPIO_InitStruct.Alternate = GPIO_AF6_SPI3;
  HAL_GPIO_Init(GPIOB, &GPIO_InitStruct);

  /*Configure GPIO pins : PB8 PB9 */
  GPIO_InitStruct.Pin = GPIO_PIN_8|GPIO_PIN_9;
  GPIO_InitStruct.Mode = GPIO_MODE_AF_OD;
  GPIO_InitStruct.Pull = GPIO_PULLUP;
  GPIO_InitStruct.Speed = GPIO_SPEED_FREQ_VERY_HIGH;
  GPIO_InitStruct.Alternate = GPIO_AF4_I2C1;
  HAL_GPIO_Init(GPIOB, &GPIO_InitStruct);

}

void Error_Handler(void)
{
  __disable_irq();
  while (1)
  {
  }
}
